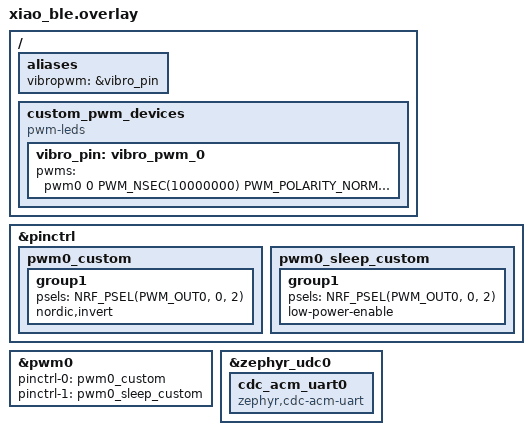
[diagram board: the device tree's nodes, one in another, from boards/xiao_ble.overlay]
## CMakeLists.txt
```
cmake_minimum_required(VERSION 3.20.0)
find_package(Zephyr REQUIRED HINTS $ENV{ZEPHYR_BASE})

project(Zephyr_PWM_test)

target_sources(app PRIVATE src/main.c)
```

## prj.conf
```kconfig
# Podstawy: PWM i Logi
CONFIG_PWM=y
CONFIG_LOG=y

# Kontrola Zegara (Wymagana przez sprzętowy kontroler USB w nRF!)
CONFIG_CLOCK_CONTROL=y

# Wymuszamy KLASYCZNY stos USB i twardo BLOKUJEMY nowy (żeby uniknąć konfliktów)
CONFIG_USB_DEVICE_STACK=y
CONFIG_USB_DEVICE_STACK_NEXT=n
CONFIG_USB_DEVICE_PRODUCT="XIAO Wibracje"
CONFIG_USB_DEVICE_VID=0x2886
CONFIG_USB_DEVICE_PID=0x002B
CONFIG_USB_DEVICE_INITIALIZE_AT_BOOT=n

# Obsługa portu szeregowego
CONFIG_SERIAL=y
CONFIG_UART_INTERRUPT_DRIVEN=y
CONFIG_UART_LINE_CTRL=y
```

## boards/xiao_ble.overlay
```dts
#include <zephyr/dt-bindings/pwm/pwm.h>
#include <zephyr/dt-bindings/pinctrl/nrf-pinctrl.h>

/ {
    aliases {
        vibropwm = &vibro_pin;
    };

    custom_pwm_devices {
        compatible = "pwm-leds";
        vibro_pin: vibro_pwm_0 {
            pwms = <&pwm0 0 PWM_NSEC(10000000) PWM_POLARITY_NORMAL>;
        };
    };
};

&pinctrl {
    pwm0_custom: pwm0_custom {
        group1 {
            psels = <NRF_PSEL(PWM_OUT0, 0, 2)>;
            nordic,invert;
        };
    };

    pwm0_sleep_custom: pwm0_sleep_custom {
        group1 {
            psels = <NRF_PSEL(PWM_OUT0, 0, 2)>;
            low-power-enable;
        };
    };
};

&pwm0 {
    status = "okay";
    pinctrl-0 = <&pwm0_custom>;
    pinctrl-1 = <&pwm0_sleep_custom>;
    pinctrl-names = "default", "sleep";
};

&zephyr_udc0 {
    cdc_acm_uart0: cdc_acm_uart0 {
        compatible = "zephyr,cdc-acm-uart";
    };
};
```

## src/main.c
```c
#include <zephyr/kernel.h>
#include <zephyr/drivers/pwm.h>
#include <zephyr/drivers/uart.h>
#include <zephyr/usb/usb_device.h>
#include <zephyr/logging/log.h>
#include <stdlib.h>
#include <string.h>

LOG_MODULE_REGISTER(main, LOG_LEVEL_INF);

static const struct pwm_dt_spec vibro_pwm = PWM_DT_SPEC_GET(DT_ALIAS(vibropwm));
static const struct device *usb_uart = DEVICE_DT_GET_ONE(zephyr_cdc_acm_uart);

static uint32_t current_freq = 5000;
static uint32_t current_duty = 50;
static bool motor_enabled = false;

#define RX_BUF_SIZE 64
static char rx_buf[RX_BUF_SIZE];
static int rx_buf_pos = 0;

void update_motor(void) {
    if (!motor_enabled || current_duty == 0 || current_freq == 0) {
        pwm_set_dt(&vibro_pwm, 0, 0);
        LOG_INF("Status: WYLACZONY");
        return;
    }

    if (current_duty > 100) current_duty = 100;

    uint32_t period_ns = 1000000000UL / current_freq;
    uint32_t pulse_ns = (period_ns * current_duty) / 100;

    pwm_set_dt(&vibro_pwm, period_ns, pulse_ns);
    LOG_INF("Status: WLACZONY | Freq: %u Hz | Duty: %u %%", current_freq, current_duty);
}

void process_command(const char *cmd) {
    if (strlen(cmd) < 3) return;

    if (cmd[0] == 'D' && cmd[1] == ':') {
        current_duty = atoi(&cmd[2]);
    } else if (cmd[0] == 'F' && cmd[1] == ':') {
        current_freq = atoi(&cmd[2]);
    } else if (cmd[0] == 'E' && cmd[1] == ':') {
        motor_enabled = (atoi(&cmd[2]) != 0);
    }
    
    update_motor();
}

static void uart_interrupt_handler(const struct device *dev, void *user_data) {
    uart_irq_update(dev);

    if (uart_irq_rx_ready(dev)) {
        int data_length;
        uint8_t c;

        while ((data_length = uart_fifo_read(dev, &c, 1)) > 0) {
            if (c == '\n' || c == '\r') {
                if (rx_buf_pos > 0) {
                    rx_buf[rx_buf_pos] = '\0';
                    process_command(rx_buf);
                    rx_buf_pos = 0; 
                }
            } else if (rx_buf_pos < RX_BUF_SIZE - 1) {
                rx_buf[rx_buf_pos++] = c;
            }
        }
    }
}

int main(void) {
    if (!pwm_is_ready_dt(&vibro_pwm)) {
        LOG_ERR("Blad: PWM nie jest gotowe!");
        return 0;
    }

    if (!device_is_ready(usb_uart)) {
        LOG_ERR("Blad: USB UART nie jest gotowe! Czy wezel cdc-acm jest w overlay?");
        return 0;
    }

    /* Inicjalizacja stosu USB Zephyra */
    int ret = usb_enable(NULL);
    if (ret != 0) {
        LOG_ERR("Blad inicjalizacji USB!");
        return 0;
    }

    uart_irq_callback_set(usb_uart, uart_interrupt_handler);
    uart_irq_rx_enable(usb_uart);

    LOG_INF("System USB gotowy. Czekam na komendy z aplikacji w Pythonie...");
    update_motor(); 

    while (1) {
        k_msleep(1000); 
    }
    return 0;
}
```
